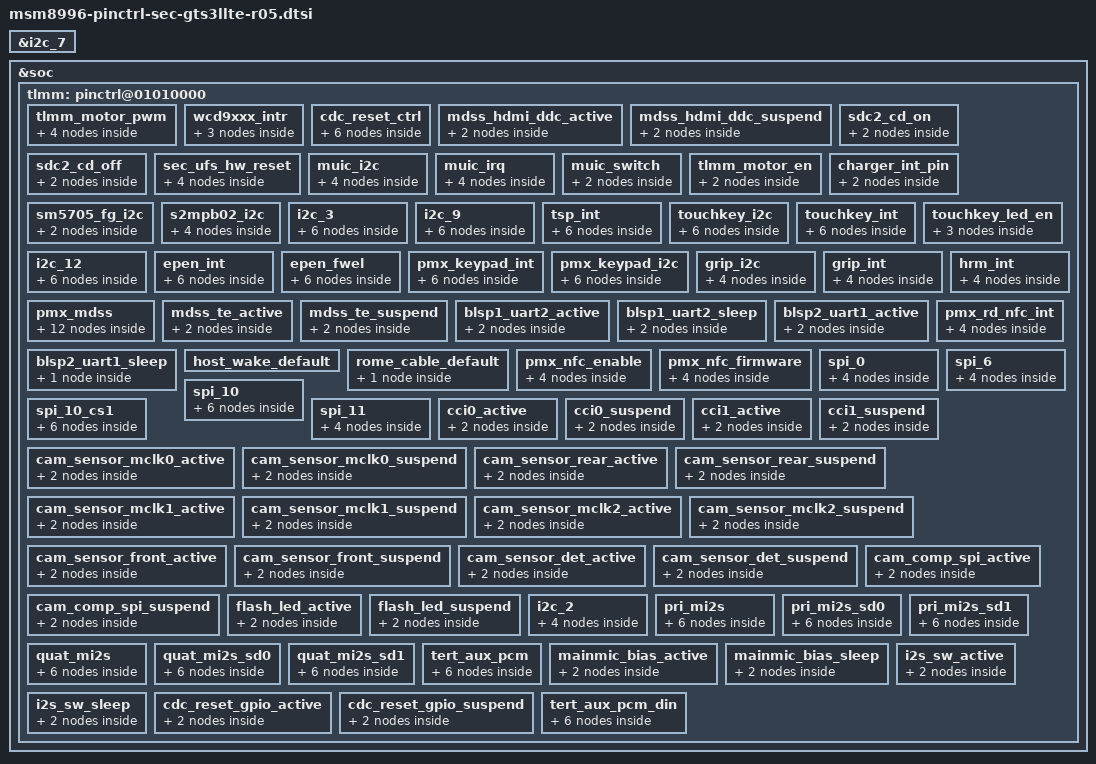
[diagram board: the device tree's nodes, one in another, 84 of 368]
/* Copyright (c) 2014-2015, The Linux Foundation. All rights reserved.
 *
 * This program is free software; you can redistribute it and/or modify
 * it under the terms of the GNU General Public License version 2 and
 * only version 2 as published by the Free Software Foundation.
 *
 * This program is distributed in the hope that it will be useful,
 * but WITHOUT ANY WARRANTY; without even the implied warranty of
 * MERCHANTABILITY or FITNESS FOR A PARTICULAR PURPOSE.  See the
 * GNU General Public License for more details.
 */

&i2c_7 {
	/delete-node/ silabs4705@11;
};

&soc {
	tlmm: pinctrl@01010000 {
		/delete-node/ pmx_fm_int;
		/delete-node/ mdss_hdmi_ddc_active;
		/delete-node/ mdss_hdmi_ddc_suspend;
		/delete-node/ cnss_pins;
		/delete-node/ pmx_rd_nfc_int;
		/delete-node/ i2c_6;

		/* add pinctrl for motor  */
		tlmm_motor_pwm {
			motor_pwm_active: motor_pwm_active {
				tlmm_motor_pwm {
					pins = "gpio57";
					drive-strength = <2>;
					function = "gcc_gp1_clk_a";
					bias-pull-down; /* PULL DOWN */
				};
			};
			motor_pwm_suspend: motor_pwm_suspend {
				tlmm_motor_pwm {
					pins = "gpio57";
					drive-strength = <2>;
					function = "gpio";
					bias-pull-down; /* PULL DOWN */
					output-low;
				};
			};
		};

		/delete-node/ wcd9xxx_intr;
		wcd9xxx_intr {
			wcd_intr_default: wcd_intr_default{
				mux {
					pins = "gpio79";
					function = "gpio";
				};

				config {
					pins = "gpio79";
					drive-strength = <2>; /* 2 mA */
					bias-pull-down; /* pull down */
					input-enable;
				};
			};
		};

		/delete-node/ cdc_reset_ctrl;
		cdc_reset_ctrl {
			cdc_reset_sleep: cdc_reset_sleep {
				mux {
					pins = "gpio74";
					function = "gpio";
				};
				config {
					pins = "gpio74";
					drive-strength = <16>;
					bias-disable;
					output-low;
				};
			};
			cdc_reset_active:cdc_reset_active {
				mux {
					pins = "gpio74";
					function = "gpio";
				};
				config {
					pins = "gpio74";
					drive-strength = <16>;
					bias-disable;
					output-high;
				};
			};
		};

		mdss_hdmi_ddc_active: mdss_hdmi_ddc_active {
			mux {
				pins = "gpio93", "gpio94";
				function = "hdmi_ddc";
			};

			config {
				pins = "gpio93", "gpio94";
				drive-strength = <2>;
				bias-pull-up;
			};
		};

		mdss_hdmi_ddc_suspend: mdss_hdmi_ddc_suspend {
			mux {
				pins = "gpio93", "gpio94";
				function = "hdmi_ddc";
			};

			config {
				pins = "gpio93", "gpio94";
				drive-strength = <2>;
				bias-pull-down;
			};
		};

		sdc2_cd_on: sdc2_cd_on {
			mux {
				pins = "gpio95";
				function = "gpio";
			};

			config {
				pins = "gpio95";
				bias-disable;           /* no pull */
				drive-strength = <16>;	/* 16 MA */
				input-high;
			};
		};

		sdc2_cd_off: sdc2_cd_off {
			mux {
				pins = "gpio95";
				function = "gpio";
			};

			config {
				pins = "gpio95";
				bias-disable;           /* no pull */
				drive-strength = <2>;	/* 2 MA */
				input-high;
			};
		};

		sec_ufs_hw_reset {
			ufs_power_on: ufs_power_on {
				sec_ufs_hw_reset {
					pins = "gpio89";
					bias-disable;
					output-low;
				};
			};
			ufs_power_off: ufs_power_off {
				sec_ufs_hw_reset {
					pins = "gpio89";
					bias-disable;
					output-high;
				};
			};
		};

		muic_i2c {
			muic_i2c_active: muic_i2c_active {
				muic_i2c {
					pins = "gpio33", "gpio32";
					drive-strength = <2>;
					function = "gpio";
					bias-disable;
				};
			};
			muic_i2c_suspend: muic_i2c_suspend {
				muic_i2c {
					pins = "gpio33", "gpio32";
					drive-strength = <2>;
					function = "gpio";
					bias-disable;
				};
			};
		};

		muic_irq {
			muic_irq_active: muic_irq_active {
				muic_irq {
					pins = "gpio132";
					drive-strength = <2>;
					function = "gpio";
					bias-disable;
				};
			};
			muic_irq_suspend: muic_irq_suspend {
				muic_irq {
					pins = "gpio132";
					drive-strength = <2>;
					function = "gpio";
					bias-disable;
				};
			};
		};

		muic_switch {
			muic_switch_default: muic_switch_default {
				muic_switch {
					pins = "gpio1";
					drive-strength = <2>;
					function = "gpio";
					bias-pull-down; /* pull down */
					output-low;
				};
			};
		};

		tlmm_motor_en {
			motor_en_default: motor_en_default {
				tlmm_motor_en {
					pins = "gpio120";
					drive-strength = <2>;
					function = "gpio";
					bias-disable; /* No PULL */
					output-low;
				};
			};
		};

		charger_int_pin {
			charger_int_active: charger_int_active {
				charger_int_pin {
				    pins = "gpio38";
				    drive-strength = <2>;
					bias-pull-up;
				};
			};
		};

		sm5705_fg_i2c {
			sm5705_fg_i2c_active: sm5705_fg_i2c_active {
				sm5705_fg_i2c {
					pins = "gpio6", "gpio7";
					drive-strength = <2>;
					function = "gpio";
					bias-disable;
				};
			};
		};

		s2mpb02_i2c {
			s2mpb02_i2c_active: s2mpb02_i2c_active {
				s2mpb02_i2c {
					pins = "gpio87", "gpio88";
					drive-strength = <2>;
					bias-disable;
					function = "blsp_i2c12";
				};
			};
			s2mpb02_i2c_suspend: s2mpb02_i2c_suspend {
				s2mpb02_i2c {
					pins = "gpio87", "gpio88";
					drive-strength = <2>;
					bias-disable;
					function = "blsp_i2c12";
				};
			};
		};

		/delete-node/ i2c_3;
		i2c_3 {
			i2c_3_active: i2c_3_active {
				mux {
					pins = "gpio47", "gpio48";
					function = "blsp_i2c3";
				};

				config {
					pins = "gpio47", "gpio48";
					drive-strength = <2>;
					bias-disable;
				};
			};

			i2c_3_sleep: i2c_3_sleep {
				mux {
					pins = "gpio47", "gpio48";
					function = "blsp_i2c3";
				};

				config {
					pins = "gpio47", "gpio48";
					drive-strength = <2>;
					bias-disable;
				};
			};
		};

		i2c_9 {
			i2c_9_active: i2c_9_active {
				mux {
					pins = "gpio51", "gpio52";
					function = "blsp_i2c9";
				};

				config {
					pins = "gpio51", "gpio52";
					drive-strength = <2>;
					bias-disable;
				};
			};

			i2c_9_sleep: i2c_9_sleep {
				mux {
					pins = "gpio51", "gpio52";
					function = "blsp_i2c9";
				};

				config {
					pins = "gpio51", "gpio52";
					drive-strength = <2>;
					bias-disable;
				};
			};
		};

		tsp_int {
			tsp_int_active: tsp_int_active {
				mux {
					pins = "gpio123";
					function = "gpio";
				};

				config {
					pins = "gpio123";
					drive-strength = <2>;
					bias-disable;
				};
			};
			tsp_int_suspend: tsp_int_suspend {
				mux {
					pins = "gpio123";
					function = "gpio";
				};

				config {
					pins = "gpio123";
					drive-strength = <2>;
					bias-pull-down;
				};
			};
		};

		touchkey_i2c {
			touchkey_i2c_active: touchkey_i2c_active {
				mux {
					pins = "gpio21", "gpio22";
					function = "gpio";
				};

				config {
					pins = "gpio21", "gpio22";
					drive-strength = <2>;
					bias-disable;
				};
			};
			touchkey_i2c_suspend: touchkey_i2c_suspend {
				mux {
					pins = "gpio21", "gpio22";
					function = "gpio";
				};

				config {
					pins = "gpio21", "gpio22";
					drive-strength = <2>;
					bias-disable;
				};
			};
		};

		touchkey_int {
			touchkey_int_active: touchkey_int_active {
				mux {
					pins = "gpio64";
					function = "gpio";
				};

				config {
					pins = "gpio64";
					drive-strength = <2>;
					bias-disable;
				};
			};
			touchkey_int_suspend: touchkey_int_suspend {
				mux {
					pins = "gpio64";
					function = "gpio";
				};

				config {
					pins = "gpio64";
					drive-strength = <2>;
					bias-disable;
				};
			};
		};

		touchkey_led_en {
			touchkey_led_en: touchkey_led_en {
				mux {
					pins = "gpio118";
					function = "gpio";
				};

				config {
					pins = "gpio118";
					drive-strength = <2>;
					bias-disable;
					output-low;
				};
			};
		};

		/* wacom i2c */
		/delete-node/ i2c_12;
		i2c_12 {
			i2c_12_active: i2c_12_active {
				mux {
					pins = "gpio87", "gpio88";
					function = "blsp_i2c12";
				};

				config {
					pins = "gpio87", "gpio88";
					drive-strength = <2>;
					bias-disable;
				};
			};

			i2c_12_sleep: i2c_12_sleep {
				mux {
					pins = "gpio87", "gpio88";
					function = "blsp_i2c12";
				};

				config {
					pins = "gpio87", "gpio88";
					drive-strength = <2>;
					bias-disable;
				};
			};
		};

		epen_int {
			epen_int_active: epen_int_active {
				mux {
					pins = "gpio34", "gpio117";
					function = "gpio";
				};

				config {
					pins = "gpio34", "gpio117";
					drive-strength = <2>;
					bias-disable;
				};
			};

			epen_int_suspend: epen_int_suspend {
				mux {
					pins = "gpio34", "gpio117";
					function = "gpio";
				};

				config {
					pins = "gpio34", "gpio117";
					drive-strength = <2>;
					bias-disable;
				};
			};
		};

		epen_fwel {
			epen_fwel_active: epen_fwel_active {
				mux {
					pins = "gpio24";
					function = "gpio";
				};

				config {
					pins = "gpio24";
					drive-strength = <2>;
					bias-pull-down;
					output-low;
				};
			};

			epen_fwel_suspend: epen_fwel_suspend {
				mux {
					pins = "gpio24";
					function = "gpio";
				};

				config {
					pins = "gpio24";
					drive-strength = <2>;
					bias-pull-down;
					output-low;
				};
			};
		};

		/* add pingrp for keypad */
		pmx_keypad_int {
			keypad_int_active: keypad_int_active {
				mux {
					pins = "gpio54";
					function = "gpio";
				};

				config {
					pins = "gpio54";
					drive-strength = <8>;
					bias-pull-up;
				};
			};
			keypad_int_suspend: keypad_int_suspend {
				mux {
					pins = "gpio54";
					function = "gpio";
				};

				config {
					pins = "gpio54";
					drive-strength = <2>;
					bias-pull-up;
				};
			};
		};

		pmx_keypad_i2c {
			keypad_i2c_active: keypad_i2c_active {
				mux {
					pins = "gpio2",  "gpio3";
					function = "gpio";
				};

				config {
					pins = "gpio2",  "gpio3";
					drive-strength = <8>;
					bias-disable; /* NO pull */
				};
			};
			keypad_i2c_suspend: keypad_i2c_suspend {
				mux {
					pins = "gpio2",  "gpio3";
					function = "gpio";
				};

				config {
					pins = "gpio2",  "gpio3";
					drive-strength = <2>;
					bias-disable; /* NO pull */
				};
			};
		};

		grip_i2c {
			grip_i2c_active: grip_i2c_active {
				grip_i2c_active {
					pins = "gpio81", "gpio82";
					drive-strength = <2>;
					bias-disable;
				};
			};
			grip_wifi_i2c_active: grip_wifi_i2c_active {
				grip_wifi_i2c_active {
					pins = "gpio49", "gpio50";
					drive-strength = <2>;
					bias-disable;
				};
			};
		};

		grip_int {
			grip_int_active: grip_int_active {
				grip_int_active {
					pins = "gpio132";
					drive-strength = <2>;
					bias-disable;
				};
			};
			grip_wifi_int_active: grip_wifi_int_active {
				grip_wifi_int_active {
					pins = "gpio53";
					drive-strength = <2>;
					bias-disable;
				};
			};
		};

		/delete-node/ pmx_mdss;
		pmx_mdss: pmx_mdss {
			mdss_dsi_active: mdss_dsi_active {
				mux {
					pins = "gpio143", "gpio46";
					function = "gpio";
				};

				config {
					pins = "gpio143",  "gpio46";
					drive-strength = <8>; /* 8 mA */
					bias-disable = <0>; /* no pull */
				};
			};
			mdss_dsi_suspend: mdss_dsi_suspend {
				mux {
					pins = "gpio143",  "gpio46";
					function = "gpio";
				};

				config {
					pins = "gpio143",  "gpio46";
					drive-strength = <2>; /* 2 mA */
					bias-pull-down; /* pull down */
				};
			};

			mdss_dsi_tcon_rdy_active: mdss_dsi_tcon_rdy_active {
				mux {
					pins = "gpio45";
					function = "gpio";
				};

				config {
					pins = "gpio45";
					drive-strength = <8>; /* 8 mA */
					input-enable;
					bias-pull-down;
				};
			};
			mdss_dsi_tcon_rdy_suspend: mdss_dsi_tcon_rdy_suspend {
				mux {
					pins = "gpio45";
					function = "gpio";
				};

				config {
					pins = "gpio45";
					drive-strength = <2>; /* 2 mA */
					bias-pull-down; /* pull down */
				};
			};
		};

		mdss_te_active: mdss_te_active {
			mux {
				pins = "gpio10";
				function = "mdp_vsync";
			};
			config {
				pins = "gpio10";
				drive-strength = <2>; /* 8 mA */
				bias-pull-down; /* pull down*/
			};
		};


		mdss_te_suspend: mdss_te_suspend {
			mux {
				pins = "gpio10";
				function = "mdp_vsync";
			};
			config {
				pins = "gpio10";
				drive-strength = <2>; /* 2 mA */
				bias-pull-down; /* pull down */
			};
		};
		blsp1_uart2_active: blsp1_uart2_active { 
			mux { 
				pins = "gpio41", "gpio42", "gpio43", "gpio44"; 
				function = "blsp_uart2"; 
			}; 

			config { 
				pins = "gpio41", "gpio42", "gpio43", "gpio44"; 
				drive-strength = <2>; 
				bias-disable; 
			}; 
		}; 

		blsp1_uart2_sleep: blsp1_uart2_sleep { 
			mux { 
				pins = "gpio41", "gpio42", "gpio43", "gpio44"; 
				function = "gpio"; 
			}; 

			config { 
				pins = "gpio41", "gpio42", "gpio43", "gpio44"; 
				drive-strength = <2>; 
				bias-disable; 
			}; 
		}; 
		blsp2_uart1_active: blsp2_uart1_active {
			mux {
				pins = "gpio53", "gpio54";
				function = "blsp_uart7";
			};

			config {
				pins = "gpio53", "gpio54";
				drive-strength = <2>;
				bias-disable;
			};
		};

		blsp2_uart1_sleep: blsp2_uart1_sleep {
			config {
				pins = "gpio53", "gpio54";
				drive-strength = <2>;
				bias-pull-up;
			};
		};

		host_wake_default: host_wake_default {
		};
	
		rome_cable_default: rome_cable_default {
			config {
				pins = "gpio106","gpio107";
				bias-disable;
			};
		};

		hrm_int {
			hrm_int_active: hrm_int_active {
				hrm_int_active {
					pins = "gpio119";
					drive-strength = <2>;
					bias-disable;
				};
			};
			hrm_int_suspend: hrm_int_suspend {
				hrm_int_suspend {
					pins = "gpio119";
					drive-strength = <2>;
					bias-pull-down;
				};
			};
		};

		pmx_rd_nfc_int{
			nfc_int_active: nfc_int_active {
				pmx_rd_nfc_int {
					pins = "gpio126";
					drive-strength = <6>;
					bias-pull-up;
				};
			};

			nfc_int_suspend: nfc_int_suspend {
				pmx_rd_nfc_int {
					pins = "gpio126";
			    	        drive-strength = <6>;
			    	        bias-pull-up;
				};
			};
        };

		pmx_nfc_enable{
			nfc_enable_active: nfc_enable_active {
				pmx_nfc_enable{
					pins = "gpio62";
					drive-strength = <2>;
					bias-pull-down; /* PULL DOWN */
				};
			};

			nfc_enable_suspend: nfc_enable_suspend {
				pmx_nfc_enable{
					pins = "gpio62";
					drive-strength = <2>;
					bias-pull-down; /* PULL DOWN */
				};
			};
		};

        pmx_nfc_firmware{
			nfc_firmware_active: nfc_firmware_active {
				pmx_nfc_firmware{
					pins = "gpio63";
					drive-strength = <2>;
					bias-pull-down; /* PULL DOWN */
				};
			};

			nfc_firmware_suspend: nfc_firmware_suspend {
				pmx_nfc_firmware{
					pins = "gpio63";
					drive-strength = <2>;
					bias-pull-down; /* PULL DOWN */
				};
			};
		};

		spi_0 {
			spi_0_active: spi_0_active {
				spi_0 {
					pins = "gpio0", "gpio1", "gpio2", "gpio3";
					function = "blsp_spi1";
					drive-strength = <6>;
					bias-disable;
				};
			};

			spi_0_sleep: spi_0_sleep {
				spi_0 {
					pins = "gpio0", "gpio1", "gpio2", "gpio3";
					function = "blsp_spi1";
					drive-strength = <6>;
					bias-pull-down;
				};
			};
		};

		spi_6 {
			spi_6_active: spi_6_active {
				spi_6 {
					pins = "gpio25", "gpio26", "gpio27", "gpio28";
					function = "blsp_spi6";
					drive-strength = <6>;
					bias-disable;
				};
			};

			spi_6_sleep: spi_6_sleep {
				spi_6 {
					pins = "gpio25", "gpio26", "gpio27", "gpio28";
					function = "gpio";
					drive-strength = <6>;
					bias-pull-down;
				};
			};
		};

		spi_10 {
			/* MOSI, MISO, CLK */
			spi_10_active: spi_10_active {
				mux {
					pins = "gpio11";
					function = "blsp_spi10";
				};

				config {
					pins = "gpio11";
					drive-strength = <6>;
					bias-disable;
				};
			};

			spi_10_sleep: spi_10_sleep {
				mux {
					pins = "gpio11";
					function = "blsp_spi10";
				};

				config {
					pins = "gpio11";
					drive-strength = <6>;
					bias-pull-down;
				};
			};
		};

		spi_10_cs1 {
			/* CS1, CS2 */
			spi_10_cs1_active: spi_10_cs1_active {
				mux {
					pins = "gpio49", "gpio50";
					function = "blsp10_spi";
				};

				config {
					pins = "gpio49", "gpio50";
					drive-strength = <6>;
					bias-disable;
				};
			};

			spi_10_cs1_sleep: spi_10_cs1_sleep {
				mux {
					pins = "gpio49", "gpio50";
					function = "blsp10_spi";
				};

				config {
					pins = "gpio49", "gpio50";
					drive-strength = <6>;
					bias-pull-down;
				};
			};
		};

		spi_11 {
			spi_11_active: spi_11_active {
				spi_11 {
					pins = "gpio58", "gpio59", "gpio60", "gpio61";
					function = "blsp_spi11";
					drive-strength = <6>;
					bias-disable;
				};
			};

			spi_11_sleep: spi_11_sleep {
				spi_11 {
					pins = "gpio58", "gpio59", "gpio60", "gpio61";
					function = "gpio";
					drive-strength = <6>;
					bias-pull-down;
					input-low;
				};
			};
		};

		/* pin-ctrl for camera sensor */
		cci0_active: cci0_active {
			mux {
				/* CLK, DATA */
				pins = "gpio17","gpio18"; // Only 2
				function = "cci_i2c";
			};
			config {
				pins = "gpio17","gpio18";
				bias-disable; /* No PULL */
				drive-strength = <2>; /* 2 MA */
			};
		};

		cci0_suspend: cci0_suspend {
			mux {
				/* CLK, DATA */
				pins = "gpio17","gpio18";
				function = "gpio";
			};
			config {
				pins = "gpio17","gpio18";
				bias-pull-down;
				drive-strength = <2>; /* 2 MA */
			};
		};

		cci1_active: cci1_active {
			mux {
				/* CLK, DATA */
				pins = "gpio19","gpio20";
				function = "cci_i2c";
			};
			config {
				pins = "gpio19","gpio20";
				bias-disable; /* No PULL */
				drive-strength = <2>; /* 2 MA */
			};
		};

		cci1_suspend: cci1_suspend {
			mux {
				/* CLK, DATA */
				pins = "gpio19","gpio20";
				function = "gpio";
			};
			config {
				pins = "gpio19","gpio20";
				bias-pull-down;
				drive-strength = <2>; /* 2 MA */
			};
		};

		cam_sensor_mclk0_active: cam_sensor_mclk0_active {
			/* MCLK0 */
			mux {
				/* CLK, DATA */
				pins = "gpio13";
				function = "cam_mclk";
			};
			config {
				pins = "gpio13";
				bias-disable; /* No PULL */
				drive-strength = <4>; /* 4 MA */
			};
		};

		cam_sensor_mclk0_suspend: cam_sensor_mclk0_suspend {
			/* MCLK0 */
			mux {
				/* CLK, DATA */
				pins = "gpio13";
				function = "cam_mclk";
			};
			config {
				pins = "gpio13";
				bias-pull-down; /* PULL DOWN */
				drive-strength = <4>; /* 4 MA */
			};
		};

		cam_sensor_rear_active: cam_sensor_rear_active {
			/* RESET */
			mux {
				pins = "gpio9", "gpio30";
				function = "gpio";
			};
			config {
				pins = "gpio9", "gpio30";
				bias-disable; /* No PULL */
				drive-strength = <2>; /* 2 MA */
			};
		};

		cam_sensor_rear_suspend: cam_sensor_rear_suspend{
			/* RESET */
			mux {
				pins = "gpio9", "gpio30";
				function = "gpio";
			};
			config {
				pins = "gpio9", "gpio30";
				bias-pull-down;
				drive-strength = <2>; /* 2 MA */
			};
		};

		cam_sensor_mclk1_active: cam_sensor_mclk1_active{
			/* MCLK1 */
			mux {
				/* CLK, DATA */
				pins = "gpio14";
				function = "cam_mclk";
			};
			config {
				pins = "gpio14";
				bias-disable; /* No PULL */
				drive-strength = <2>; /* 2 MA */
			};
		};

		cam_sensor_mclk1_suspend: cam_sensor_mclk1_suspend {
			/* MCLK1 */
			mux {
				/* CLK, DATA */
				pins = "gpio14";
				function = "cam_mclk";
			};
			config {
				pins = "gpio14";
				bias-pull-down; /* PULL DOWN */
				drive-strength = <2>; /* 2 MA */
			};
		};

		cam_sensor_mclk2_active: cam_sensor_mclk2_active {
			/* MCLK1 */
			mux {
				/* CLK, DATA */
				pins = "gpio15";
				function = "cam_mclk";
			};
			config {
				pins = "gpio15";
				bias-disable; /* No PULL */
				drive-strength = <4>; /* 4 MA */
			};
		};

		cam_sensor_mclk2_suspend: cam_sensor_mclk2_suspend{
			/* MCLK1 */
			mux {
				/* CLK, DATA */
				pins = "gpio15";
				function = "cam_mclk";
			};
			config {
				pins = "gpio15";
				bias-pull-down; /* PULL DOWN */
				drive-strength = <4>; /* 4 MA */
			};
		};

		cam_sensor_front_active: cam_sensor_front_active{
			/* RESET */
			mux {
				pins = "gpio8", "gpio40";
				function = "gpio";
			};

			config {
				pins = "gpio8", "gpio40";
				bias-disable; /* No PULL */
				drive-strength = <2>; /* 2 MA */
			};
		};

		cam_sensor_front_suspend: cam_sensor_front_suspend{
			/* RESET */
			mux {
				pins = "gpio8", "gpio40";
				function = "gpio";
			};

			config {
				pins = "gpio8", "gpio40";
				bias-pull-down; /* PULL DOWN */
				drive-strength = <2>; /* 2 MA */
			};
		};

		cam_sensor_det_active: cam_sensor_det_active{
			/* SENSOR_DET */
			mux {
				pins = "gpio89";
				function = "gpio";
			};

			config {
				pins = "gpio89";
				bias-disable; /* No PULL */
				drive-strength = <2>; /* 2 MA */
			};
		};

		cam_sensor_det_suspend: cam_sensor_det_suspend{
			/* SENSOR_DET */
			mux {
				pins = "gpio89";
				function = "gpio";
			};

			config {
				pins = "gpio89";
				bias-disable; /* No PULL */
				drive-strength = <2>; /* 2 MA */
			};
		};

		cam_comp_spi_active: cam_comp_spi_active {
			/* COMP_RESET, COMP_INT */
			mux {
				pins = "gpio91", "gpio92";
				function = "gpio";
			};

			config {
				pins = "gpio91", "gpio92";
				bias-pull-up;
				drive-strength = <2>; /* 2 MA */
			};
		};

		cam_comp_spi_suspend: cam_comp_spi_suspend {
			/* COMP_RESET, COMP_INT */
			mux {
				pins = "gpio91", "gpio92";
				function = "gpio";
			};

			config {
				pins = "gpio91", "gpio92";
				bias-pull-down;
				drive-strength = <2>; /* 2 MA */
			};
		};

		flash_led_active: flash_led_active {
			mux {
				pins = "gpio11","gpio12";
				function = "gpio";
			};

			config {
				pins = "gpio11","gpio12";
				bias-disable; /* No PULL */
				drive-strength = <2>; /* 2 MA */
			};
		};

		flash_led_suspend: flash_led_suspend {
			mux {
				pins = "gpio11","gpio12";
				function = "gpio";
			};

			config {
				pins = "gpio11","gpio12";
				bias-disable; /* No PULL */
				drive-strength = <2>; /* 2 MA */
				output-low;
			};
		};

		i2c_2 {
			i2c_2_active: i2c_2_active {
				i2c_2 {
					pins = "gpio43", "gpio44";
					function = "blsp_i2c2";
					drive-strength = <2>;
					bias-disable;
				};
			};

			i2c_2_sleep: i2c_2_sleep {
				i2c_2 {
					pins = "gpio43", "gpio44";
					function = "blsp_i2c2";
					drive-strength = <2>;
					bias-pull-down;
				};
			};
		};

		pri_mi2s {
			pri_mi2s_sleep: pri_mi2s_sleep {
				mux {
					pins = "gpio65", "gpio66";
					function = "pri_mi2s";
				};

				config {
					pins = "gpio65", "gpio66";
					drive-strength = <2>;   /* 2 mA */
					bias-pull-down;         /* PULL DOWN */
				};
			};
			pri_mi2s_active: pri_mi2s_active {
				mux {
					pins = "gpio65", "gpio66";
					function = "pri_mi2s";
				};

				config {
					pins = "gpio65", "gpio66";
					drive-strength = <8>;   /* 2 mA */
					bias-disable;           /* NO PULL */
					output-high;
				};
			};
		};

		pri_mi2s_sd0 {
			pri_mi2s_sd0_sleep: pri_mi2s_sd0_sleep {
				mux {
					pins = "gpio67";
					function = "pri_mi2s";
				};

				config {
					pins = "gpio67";
					drive-strength = <2>;   /* 2 mA */
					bias-pull-down;         /* PULL DOWN */
				};
			};
			pri_mi2s_sd0_active: pri_mi2s_sd0_active {
				mux {
					pins = "gpio67";
					function = "pri_mi2s";
				};

				config {
					pins = "gpio67";
					drive-strength = <8>;   /* 8 mA */
					bias-pull-down;           /* PULL DOWN */
				};
			};
		};

		pri_mi2s_sd1 {
			pri_mi2s_sd1_sleep: pri_mi2s_sd1_sleep {
				mux {
					pins = "gpio68";
					function = "pri_mi2s";
				};

				config {
					pins = "gpio68";
					drive-strength = <2>;   /* 2 mA */
					bias-pull-down;         /* PULL DOWN */
				};
			};
			pri_mi2s_sd1_active: pri_mi2s_sd1_active {
				mux {
					pins = "gpio68";
					function = "pri_mi2s";
				};

				config {
					pins = "gpio68";
					drive-strength = <8>;   /* 8 mA */
					bias-pull-down;         /* PULL DOWN */
				};
			};
		};

		quat_mi2s {
			quat_mi2s_sleep: quat_mi2s_sleep {
				mux {
					pins = "gpio58", "gpio59";
					function = "qua_mi2s";
				};

				config {
					pins = "gpio58", "gpio59";
					drive-strength = <2>;   /* 2 mA */
					bias-pull-down;         /* PULL DOWN */
				};
			};
			quat_mi2s_active: quat_mi2s_active {
				mux {
					pins = "gpio58", "gpio59";
					function = "qua_mi2s";
				};

				config {
					pins = "gpio58", "gpio59";
					drive-strength = <8>;   /* 2 mA */
					bias-disable;           /* NO PULL */
					output-high;
				};
			};
		};

		quat_mi2s_sd0 {
			quat_mi2s_sd0_sleep: quat_mi2s_sd0_sleep {
				mux {
					pins = "gpio60";
					function = "gpio";
				};

				config {
					pins = "gpio60";
					drive-strength = <2>;   /* 2 mA */
					bias-pull-down;             /* PULL DOWN */
				};
			};
			quat_mi2s_sd0_active: quat_mi2s_sd0_active {
				mux {
					pins = "gpio60";
					function = "gpio";
				};

				config {
					pins = "gpio60";
					drive-strength = <8>;   /* 8 mA */
					input-enable;
					bias-pull-down;             /* PULL DOWN */
				};
			};
		};

		quat_mi2s_sd1 {
			quat_mi2s_sd1_sleep: quat_mi2s_sd1_sleep {
				mux {
					pins = "gpio61";
					function = "qua_mi2s";
				};

				config {
					pins = "gpio61";
					drive-strength = <2>;   /* 2 mA */
					bias-pull-down;           /* PULL DOWN */
				};
			};
			quat_mi2s_sd1_active: quat_mi2s_sd1_active {
				mux {
					pins = "gpio61";
					function = "qua_mi2s";
				};

				config {
					pins = "gpio61";
					drive-strength = <8>;   /* 8 mA */
					bias-pull-down;           /* PULL DOWN */
				};
			};
		};

		tert_aux_pcm {
			tert_aux_pcm_sleep: tert_aux_pcm_sleep {
				mux {
					pins = "gpio75", "gpio76", "gpio77";
					function = "ter_mi2s";
				};

				config {
					pins = "gpio75", "gpio76", "gpio77";
					drive-strength = <2>;   /* 2 mA */
					bias-pull-down;         /* PULL DOWN */
				};
			};
			tert_aux_pcm_active: tert_aux_pcm_active {
				mux {
					pins = "gpio75", "gpio76", "gpio77";
					function = "ter_mi2s";
				};

				config {
					pins = "gpio75", "gpio76", "gpio77";
					drive-strength = <8>;   /* 8 mA */
					bias-disable;           /* NO PULL */
					output-high;
				};
			};
		};

		mainmic_bias_active: mainmic_bias_active {
			mux {
				pins = "gpio29";
				function = "gpio";
			};
			config {
				pins = "gpio29";
				drive-strength = <2>;
				bias-pull-down;
				input-low;
			};
		};

		mainmic_bias_sleep: mainmic_bias_sleep {
			mux {
				pins = "gpio29";
				function = "gpio";
			};
			config {
				pins = "gpio29";
				drive-strength = <2>;
				bias-pull-down;
				input-low;
			};
		};

		i2s_sw_active: i2s_sw_active {
			mux {
				pins = "gpio63";
				function = "gpio";
			};
			config {
				pins = "gpio63";
				drive-strength = <2>;
				bias-pull-up; /* PULL UP */
				output-high;
			};
		};

		i2s_sw_sleep: i2s_sw_sleep {
			mux {
				pins = "gpio63";
				function = "gpio";
			};
			config {
				pins = "gpio63";
				drive-strength = <2>;
				bias-pull-up; /* PULL UP */
				output-high;
			};
		};

		cdc_reset_gpio_active: cdc_reset_gpio_active {
			mux {
				pins = "gpio74";
				function = "gpio";
			};
			config {
				pins = "gpio74";
				drive-strength = <16>;   /* 16 mA */
				bias-disable; /* No PULL */
				output-high;
			};
		};

		cdc_reset_gpio_suspend: cdc_reset_gpio_suspend {
			mux {
				pins = "gpio74";
				function = "gpio";
			};
			config {
				pins = "gpio74";
				drive-strength = <16>;   /* 16 mA */
				bias-disable; /* No PULL */
				output-low;
			};
		};

		tert_aux_pcm_din {
			tert_aux_pcm_din_sleep: tert_aux_pcm_din_sleep {
				mux {
					pins = "gpio78";
					function = "ter_mi2s";
				};

				config {
					pins = "gpio78";
					drive-strength = <2>;   /* 2 mA */
					bias-pull-down;         /* PULL DOWN */
				};
			};
			tert_aux_pcm_din_active: tert_aux_pcm_din_active {
				mux {
					pins = "gpio78";
					function = "ter_mi2s";
				};

				config {
					pins = "gpio78";
					drive-strength = <8>;   /* 8 mA */
					bias-disable;           /* NO PULL */
				};
			};
		};
	};
};
